# nrf9160 register map
Vendor: Nordic Semiconductor; Series: nrf91; File version: 1
CPU: CM33 r0p4, little endian, MPU, FPU, 3 interrupt priority bits, 69 interrupts
Registers are 32-bit, read-write, reset 0x0 unless marked. A register's access mark holds for its fields unless they carry their own. Offsets are from the block's base; [hi:lo] are bit positions.

## CC_DOUT_S — CRYPTOCELL Data OUT interface
Base 0x50841000; alternate view of CC_AES_S
0xC00 DOUT_BUFFER ro — Cryptographic results directly accessible by the CPU.
  [31:0] DATA — This address can be used by the CPU to read data directly from the DOUT buffer.
0xD20 DOUT_DMA_MEM_BUSY ro — Status register for DOUT DMA engine activity when accessing memory.
  [0] STATUS — DOUT memory DMA engine status.
    0=Idle (DOUT memory DMA engine is idle); 1=Busy (DOUT memory DMA engine is busy)
0xD28 DST_MEM_ADDR wo — Data destination address in memory.
  [31:0] ADDR — Destination address in memory.
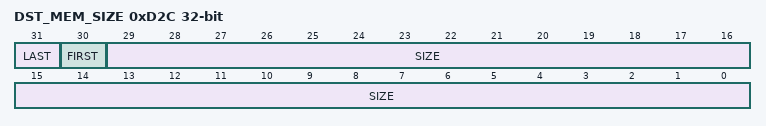
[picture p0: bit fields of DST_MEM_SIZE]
0xD2C DST_MEM_SIZE wo — The number of bytes to be written to memory.
  [31] LAST — This field is reserved
  [30] FIRST — This field is reserved
  [29:0] SIZE — Total number of bytes to write to memory.
0xD30 DST_SRAM_ADDR — Data destination address in RNG SRAM.
  [31:0] ADDR — Destination address in RNG SRAM.
0xD34 DST_SRAM_SIZE wo — The number of bytes to be written to RNG SRAM.
  [31:0] SIZE — Total number of bytes to write to RNG SRAM.
0xD38 DOUT_DMA_SRAM_BUSY ro — Status register for DOUT DMA engine activity when accessing RNG SRAM.
  [0] STATUS — DOUT RNG SRAM DMA engine status.
    0=Idle (DOUT RNG SRAM DMA engine is idle); 1=Busy (DOUT RNG SRAM DMA engine is busy)
0xD3C DOUT_DMA_SRAM_ENDIANNESS — Configure the endianness of DOUT DMA transactions towards RNG SRAM.
  [0] ENDIAN — Endianness of DOUT DMA transactions towards RNG SRAM. The default value is little-endian.
    0=LittleEndian (Use little-endian format for RNG SRAM DMA transactions); 1=BigEndian (Use big-endian format for RNG SRAM DMA transactions)
0xD44 DOUT_READ_ALIGN wo — Indication that the next CPU read from the DOUT_BUFFER is the last in the sequence. This is needed only when the data size is NOT modulo 4 (e.g. HASH padding).
  [0] LAST — Next CPU read from the DOUT_BUFFER is the last word, and the remaining read aligned content can be flushed.
    1=Flush the remaining read aligned content
0xD50 DOUT_FIFO_EMPTY ro reset 0x1 — Register indicating if DOUT FIFO is empty or if more data will come.
  [0] STATUS — DOUT FIFO status
    0=NotEmpty (DOUT FIFO is not empty, and more data will come); 1=Empty (DOUT FIFO is empty)
0xD58 DOUT_SW_RESET wo — Reset the DOUT DMA engine.
  [0] RESET — Writing any value to this address resets the DOUT DMA engine. The reset takes 4 CPU clock cycles to complete.
    1=Enable (Reset DOUT DMA engine.)

## CC_MISC_S — CRYPTOCELL MISC interface
Base 0x50841000; alternate view of CC_AES_S
0x810 AES_CLK wo — Clock control for the AES engine.
  [0] ENABLE — Enables clock for the AES engine.
    0=Disable clock for the AES engine; 1=Enable clock for the AES engine
0x818 HASH_CLK wo — Clock control for the HASH engine.
  [0] ENABLE — Enables clock for the HASH engine.
    0=Disable clock for the HASH engine; 1=Enable clock for the HASH engine
0x81C PKA_CLK wo — Clock control for the PKA engine.
  [0] ENABLE — Enables clock for the PKA engine.
    0=Disable clock for the PKA engine; 1=Enable clock for the PKA engine
0x820 DMA_CLK wo — Clock control for the DMA engines.
  [0] ENABLE — Enables clock for the DMA engines.
    0=Disable clock for the DMA engines; 1=Enable clock for the DMA engines
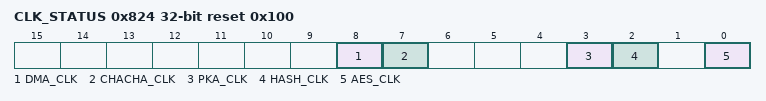
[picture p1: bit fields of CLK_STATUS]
0x824 CLK_STATUS ro reset 0x100 — CRYPTOCELL clocks status register.
  [8] DMA_CLK — Status of DMA engines clock.
    0=Disabled (Clocks for DMA engines are disabled); 1=Enabled (Clocks for DMA engines are enabled)
  [7] CHACHA_CLK — Status of CHACHA engine clock.
    0=Disabled (Clock for CHACHA engine is disabled); 1=Enabled (Clock for CHACHA engine is enabled)
  [3] PKA_CLK — Status of PKA engine clock.
    0=Disabled (Clock for PKA engine is disabled); 1=Enabled (Clock for PKA engine is enabled)
  [2] HASH_CLK — Status of HASH engine clock.
    0=Disabled (Clock for HASH engine is disabled); 1=Enabled (Clock for HASH engine is enabled)
  [0] AES_CLK — Status of AES engine clock.
    0=Disabled (Clock for AES engine is disabled); 1=Enabled (Clock for AES engine is enabled)
0x858 CHACHA_CLK wo — Clock control for the CHACHA engine.
  [0] ENABLE — Enables clock for the CHACHA engine.
    0=Disable clock for the CHACHA engine; 1=Enable clock for the CHACHA engine
